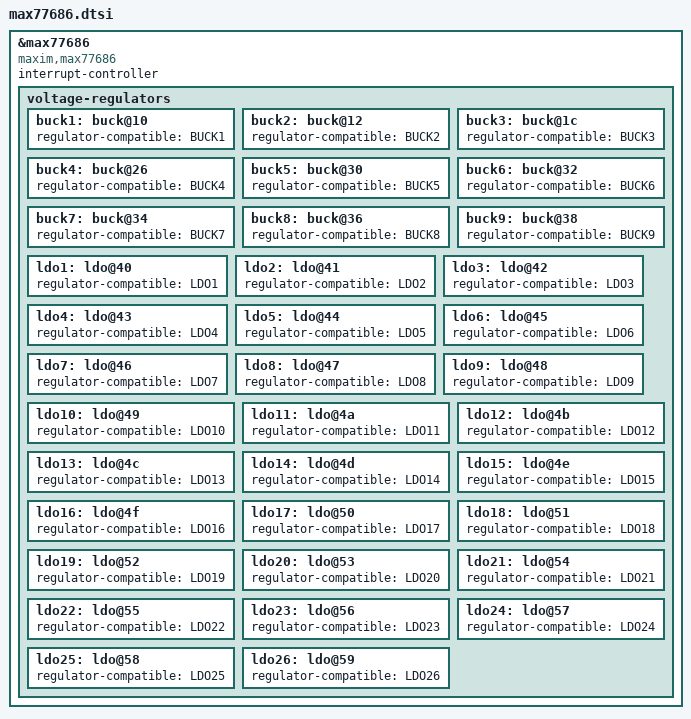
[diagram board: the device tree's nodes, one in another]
/*
 * arch/arm/boot/dts/max77686.dtsi
 *
 * This program is free software; you can redistribute it and/or modify
 * it under the terms of the GNU General Public License version 2 as
 * published by the Free Software Foundation.
 */

&max77686 {
	compatible = "maxim,max77686";

	interrupt-controller;
	#interrupt-cells = <1>;

	voltage-regulators {
		buck1: buck@10 {
			regulator-compatible = "BUCK1";
		};

		buck2: buck@12 {
			regulator-compatible = "BUCK2";
		};

		buck3: buck@1c {
			regulator-compatible = "BUCK3";
		};

		buck4: buck@26 {
			regulator-compatible = "BUCK4";
		};

		buck5: buck@30 {
			regulator-compatible = "BUCK5";
		};

		buck6: buck@32 {
			regulator-compatible = "BUCK6";
		};

		buck7: buck@34 {
			regulator-compatible = "BUCK7";
		};

		buck8: buck@36 {
			regulator-compatible = "BUCK8";
		};

		buck9: buck@38 {
			regulator-compatible = "BUCK9";
		};

		ldo1: ldo@40 {
			regulator-compatible = "LDO1";
		};

		ldo2: ldo@41 {
			regulator-compatible = "LDO2";
		};

		ldo3: ldo@42 {
			regulator-compatible = "LDO3";
		};

		ldo4: ldo@43 {
			regulator-compatible = "LDO4";
		};

		ldo5: ldo@44 {
			regulator-compatible = "LDO5";
		};

		ldo6: ldo@45 {
			regulator-compatible = "LDO6";
		};

		ldo7: ldo@46 {
			regulator-compatible = "LDO7";
		};

		ldo8: ldo@47 {
			regulator-compatible = "LDO8";
		};

		ldo9: ldo@48 {
			regulator-compatible = "LDO9";
		};

		ldo10: ldo@49 {
			regulator-compatible = "LDO10";
		};

		ldo11: ldo@4a {
			regulator-compatible = "LDO11";
		};

		ldo12: ldo@4b {
			regulator-compatible = "LDO12";
		};

		ldo13: ldo@4c {
			regulator-compatible = "LDO13";
		};

		ldo14: ldo@4d {
			regulator-compatible = "LDO14";
		};

		ldo15: ldo@4e {
			regulator-compatible = "LDO15";
		};

		ldo16: ldo@4f {
			regulator-compatible = "LDO16";
		};

		ldo17: ldo@50 {
			regulator-compatible = "LDO17";
		};

		ldo18: ldo@51 {
			regulator-compatible = "LDO18";
		};

		ldo19: ldo@52 {
			regulator-compatible = "LDO19";
		};

		ldo20: ldo@53 {
			regulator-compatible = "LDO20";
		};

		ldo21: ldo@54 {
			regulator-compatible = "LDO21";
		};

		ldo22: ldo@55 {
			regulator-compatible = "LDO22";
		};

		ldo23: ldo@56 {
			regulator-compatible = "LDO23";
		};

		ldo24: ldo@57 {
			regulator-compatible = "LDO24";
		};

		ldo25: ldo@58 {
			regulator-compatible = "LDO25";
		};

		ldo26: ldo@59 {
			regulator-compatible = "LDO26";
		};
	};
};
